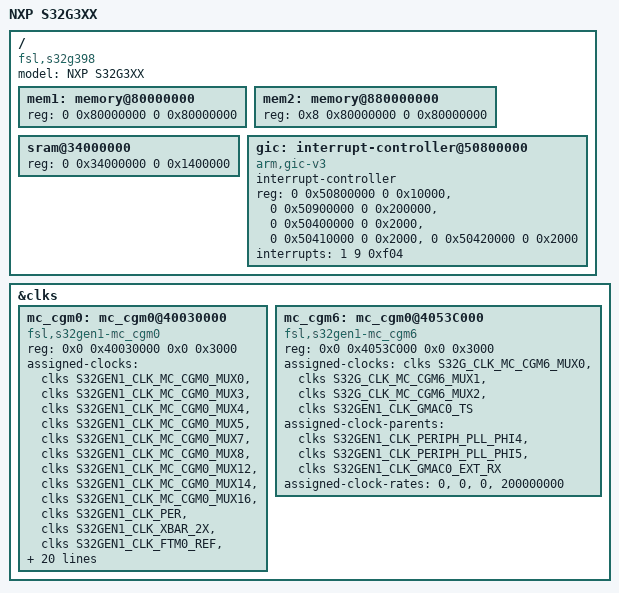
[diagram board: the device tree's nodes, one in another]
// SPDX-License-Identifier: GPL-2.0+
/*
 * Copyright 2021 NXP
 *
 * This program is free software; you can redistribute it and/or modify
 * it under the terms of the GNU General Public License as published by
 * the Free Software Foundation; either version 2 of the License, or
 * (at your option) any later version.
 */
#include <dt-bindings/clock/s32g3-clock.h>

/delete-node/ &gic;
/ {
	model = "NXP S32G3XX";
	compatible = "fsl,s32g398", "fsl,s32gen1",
			"arm,vexpress,v2p-aarch64", "arm,vexpress";

	mem1: memory@80000000 {
		device_type = "memory";
		reg = <0 0x80000000 0 0x80000000>;
	};

	mem2: memory@880000000 {
		device_type = "memory";
		reg = <0x8 0x80000000 0 0x80000000>;
	};

	sram@34000000 {
		device_type = "memory";
		reg = <0 0x34000000 0 0x1400000>;
	};

	gic: interrupt-controller@50800000 {
		compatible = "arm,gic-v3";
		#interrupt-cells = <3>;
		#address-cells = <2>;
		#size-cells = <2>;
		interrupt-controller;
		reg = <0 0x50800000 0 0x10000>, /* GIC Dist */
		      <0 0x50900000 0 0x200000>, /* GICR (RD_base + SGI_base) */
		      <0 0x50400000 0 0x2000>, /* GICC */
		      <0 0x50410000 0 0x2000>, /* GICH */
		      <0 0x50420000 0 0x2000>; /* GICV */
		interrupts = <1 9 0xf04>;
	};
};

/delete-node/ &mc_cgm0;
&clks {
	mc_cgm0: mc_cgm0@40030000 {
		compatible = "fsl,s32gen1-mc_cgm0";
		reg = <0x0 0x40030000 0x0 0x3000>;

		assigned-clocks =
			<&clks S32GEN1_CLK_MC_CGM0_MUX0>,
			<&clks S32GEN1_CLK_MC_CGM0_MUX3>,
			<&clks S32GEN1_CLK_MC_CGM0_MUX4>,
			<&clks S32GEN1_CLK_MC_CGM0_MUX5>,
			<&clks S32GEN1_CLK_MC_CGM0_MUX7>,
			<&clks S32GEN1_CLK_MC_CGM0_MUX8>,
			<&clks S32GEN1_CLK_MC_CGM0_MUX12>,
			<&clks S32GEN1_CLK_MC_CGM0_MUX14>,
			<&clks S32GEN1_CLK_MC_CGM0_MUX16>,
			<&clks S32GEN1_CLK_PER>,
			<&clks S32GEN1_CLK_XBAR_2X>,
			<&clks S32GEN1_CLK_FTM0_REF>,
			<&clks S32GEN1_CLK_FTM1_REF>,
			<&clks S32GEN1_CLK_CAN_PE>,
			<&clks S32GEN1_CLK_LIN_BAUD>,
			<&clks S32GEN1_CLK_SPI>,
			<&clks S32GEN1_CLK_QSPI_2X>,
			<&clks S32GEN1_CLK_SDHC>;
		assigned-clock-parents =
			<&clks S32GEN1_CLK_ARM_PLL_DFS1>,
			<&clks S32GEN1_CLK_PERIPH_PLL_PHI1>,
			<&clks S32GEN1_CLK_PERIPH_PLL_PHI1>,
			<&clks S32GEN1_CLK_PERIPH_PLL_PHI1>,
			<&clks S32GEN1_CLK_PERIPH_PLL_PHI2>,
			<&clks S32GEN1_CLK_PERIPH_PLL_PHI3>,
			<&clks S32GEN1_CLK_PERIPH_PLL_DFS1>,
			<&clks S32GEN1_CLK_PERIPH_PLL_DFS3>,
			<&clks S32GEN1_CLK_PERIPH_PLL_PHI7>;
		assigned-clock-rates =
			<0>,
			<0>,
			<0>,
			<0>,
			<0>,
			<0>,
			<0>,
			<0>,
			<0>,
			<80000000>,
			<0>,
			<40000000>,
			<40000000>,
			<80000000>,
			<125000000>,
			<100000000>,
			<400000000>,
			<400000000>;
	};

	mc_cgm6: mc_cgm0@4053C000 {
		compatible = "fsl,s32gen1-mc_cgm6";
		reg = <0x0 0x4053C000 0x0 0x3000>;

		assigned-clocks =
			<&clks S32G_CLK_MC_CGM6_MUX0>,
			<&clks S32G_CLK_MC_CGM6_MUX1>,
			<&clks S32G_CLK_MC_CGM6_MUX2>,
			<&clks S32GEN1_CLK_GMAC0_TS>;
		assigned-clock-parents =
			<&clks S32GEN1_CLK_PERIPH_PLL_PHI4>,
			<&clks S32GEN1_CLK_PERIPH_PLL_PHI5>,
			<&clks S32GEN1_CLK_GMAC0_EXT_RX>;
		assigned-clock-rates =
			<0>,
			<0>,
			<0>,
			<200000000>;
	};
};
